# STM32MP13xx register map
File version: 1.5
CPU: CA7 r0p0, little endian, MPU, FPU, 4 interrupt priority bits
Registers are 32-bit, read-write, reset 0x0 unless marked. A register's access mark holds for its fields unless they carry their own. Offsets are from the block's base; [hi:lo] are bit positions; {n}, {i} and the like mark numbered series; 'fields as' and 'values as' point back to an identical list.

## RCC (part 7 of 7)
Base 0x50000000
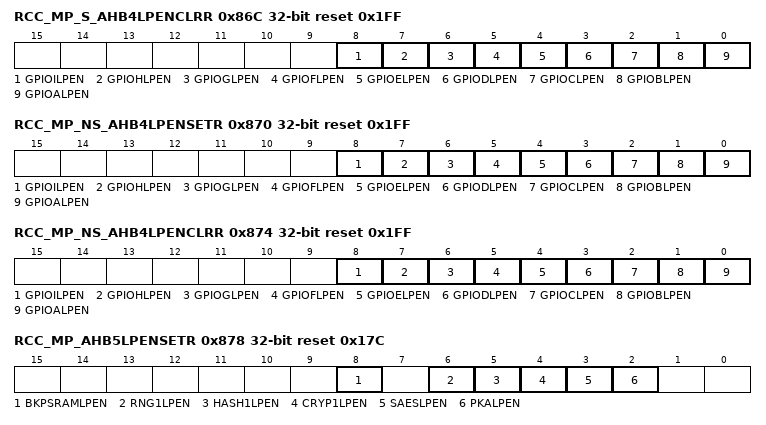
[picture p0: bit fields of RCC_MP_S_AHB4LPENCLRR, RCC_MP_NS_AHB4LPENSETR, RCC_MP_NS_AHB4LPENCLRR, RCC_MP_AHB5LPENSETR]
0x86C RCC_MP_S_AHB4LPENCLRR reset 0x1FF — This is a secure register, for disabling the clock of the secure (AHB4) GPIO ports
  [all] fields
    0=Writing '0' has no effect, reading '0' means that the peripheral clocks are disabled in CSleep; 1=Writing '1' disables the peripheral clocks in CSleep, reading '1' means that the peripheral clocks are enabled in CSleep
  [8] GPIOILPEN — GPIOI peripheral clocks enable during CSleep mode Cleared by (secure) software.
  [7] GPIOHLPEN — GPIOH peripheral clocks enable during CSleep mode Cleared by (secure) software.
  [6] GPIOGLPEN — GPIOG peripheral clocks enable during CSleep mode Cleared by (secure) software.
  [5] GPIOFLPEN — GPIOF peripheral clocks enable during CSleep mode Cleared by (secure) software.
  [4] GPIOELPEN — GPIOE peripheral clocks enable during CSleep mode Cleared by (secure) software.
  [3] GPIODLPEN — GPIOD peripheral clocks enable during CSleep mode Cleared by (secure) software.
  [2] GPIOCLPEN — GPIOC peripheral clocks enable during CSleep mode Cleared by (secure) software.
  [1] GPIOBLPEN — GPIOB peripheral clocks enable during CSleep mode Cleared by (secure) software.
  [0] GPIOALPEN — GPIOA peripheral clocks enable during CSleep mode Cleared by (secure) software.
0x870 RCC_MP_NS_AHB4LPENSETR reset 0x1FF — This is a non-secure register, for enabling the clock of the non-secure (AHB4) GPIO ports, as defined by the GPIO register file and more specifically the GPIOxSECCFGR.SECy control bit with x=A..I, and y = 0..15 (or 2 for x=I). This register is used in order to set the PERxLPEN bit of the corresponding peripheral. Writing '0' has no effect, reading will return the effective values of the corresponding bits. Writing a '1' sets the corresponding bit to '1'.
  [all] fields
    0=Writing '0' has no effect, reading '0' means that the peripheral clocks are disabled in CSleep; 1=Writing '1' enables the peripheral clocks in CSleep, reading '1' means that the peripheral clocks are enabled in CSleep
  [8] GPIOILPEN — GPIOI peripheral clocks enable during CSleep mode Set by software.
  [7] GPIOHLPEN — GPIOH peripheral clocks enable during CSleep mode Set by software.
  [6] GPIOGLPEN — GPIOG peripheral clocks enable during CSleep mode Set by software.
  [5] GPIOFLPEN — GPIOF peripheral clocks enable during CSleep mode Set by software.
  [4] GPIOELPEN — GPIOE peripheral clocks enable during CSleep mode Set by software.
  [3] GPIODLPEN — GPIOD peripheral clocks enable during CSleep mode Set by software.
  [2] GPIOCLPEN — GPIOC peripheral clocks enable during CSleep mode Set by software.
  [1] GPIOBLPEN — GPIOB peripheral clocks enable during CSleep mode Set by software.
  [0] GPIOALPEN — GPIOA peripheral clocks enable during CSleep mode Set by software.
0x874 RCC_MP_NS_AHB4LPENCLRR reset 0x1FF — This is a non-secure register, for disabling the clock of the non-secure (AHB4) GPIO ports, as defined by the GPIO register file and more specifically the GPIOxSECCFGR.SECy control bit with x=A..I, and y = 0..15 (or 2 for x=I).
  [all] fields
    values as the fields of RCC_MP_S_AHB4LPENCLRR
  [8] GPIOILPEN — GPIOI peripheral clocks enable during CSleep mode Cleared by software.
  [7] GPIOHLPEN — GPIOH peripheral clocks enable during CSleep mode Cleared by software.
  [6] GPIOGLPEN — GPIOG peripheral clocks enable during CSleep mode Cleared by software.
  [5] GPIOFLPEN — GPIOF peripheral clocks enable during CSleep mode Cleared by software.
  [4] GPIOELPEN — GPIOE peripheral clocks enable during CSleep mode Cleared by software.
  [3] GPIODLPEN — GPIOD peripheral clocks enable during CSleep mode Cleared by software.
  [2] GPIOCLPEN — GPIOC peripheral clocks enable during CSleep mode Cleared by software.
  [1] GPIOBLPEN — GPIOB peripheral clocks enable during CSleep mode Cleared by software.
  [0] GPIOALPEN — GPIOA peripheral clocks enable during CSleep mode Cleared by software.
0x878 RCC_MP_AHB5LPENSETR reset 0x17C — This register may be separately and securely write-protected at a field level, as detailed in the following register fields description. This register is used in order to set the PERxLPEN bit of the corresponding peripheral. Writing '0' has no effect, reading will return the effective values of the corresponding bits. Writing a '1' sets the corresponding bit to '1'.
  [all] fields
    values as the fields of RCC_MP_NS_AHB4LPENSETR
  [8] BKPSRAMLPEN — BKPSRAM clocks enable during CSleep mode If BKPSRAM is configured as secure via the corresponding DECPROT[1] field of the ETZPC register, a write access to this register field must be secure. A read access may be secure or non-secure. Set by software.
  [6] RNG1LPEN — RNG1 peripheral clocks enable during CSleep mode If RNG1 is configured as secure via the corresponding DECPROT[1] field of the ETZPC register, a write access to this register field must be secure. A read access may be secure or non-secure. Set by software.
  [5] HASH1LPEN — HASH peripheral clocks enable during CSleep mode If HASH is configured as secure via the corresponding DECPROT[1] field of the ETZPC register, a write access to this register field must be secure. A read access may be secure or non-secure. Set by software.
  [4] CRYP1LPEN — CRYP (3DES/AES) peripheral clocks enable during CSleep mode If CRYP is configured as secure via the corresponding DECPROT[1] field of the ETZPC register, a write access to this register field must be secure. A read access may be secure or non-secure. Set by software.
  [3] SAESLPEN — SAES peripheral clocks enable during CSleep mode If SAES is configured as secure via the corresponding DECPROT[1] field of the ETZPC register, a write access to this register field must be secure. A read access may be secure or non-secure. Set by software.
  [2] PKALPEN — PKA peripheral clocks enable during CSleep mode If PKA is configured as secure via the corresponding DECPROT[1] field of the ETZPC register, a write access to this register field must be secure. A read access may be secure or non-secure. Set by software.
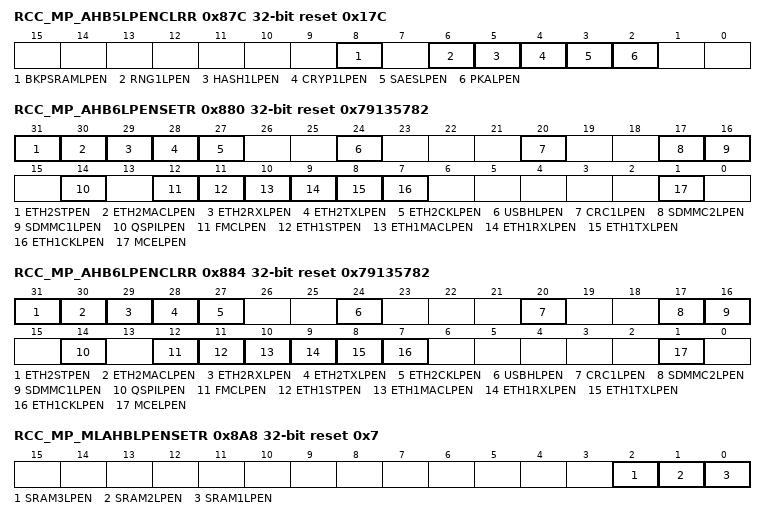
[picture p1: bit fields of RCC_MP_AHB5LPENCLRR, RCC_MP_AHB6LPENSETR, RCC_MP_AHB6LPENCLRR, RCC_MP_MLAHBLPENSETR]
0x87C RCC_MP_AHB5LPENCLRR reset 0x17C — This register may be separately and securely write-protected at a field level, as detailed in the following register fields description. This register is used in order to clear the PERxLPEN bit of the corresponding peripheral. Writing '0' has no effect, reading will return the effective values of the corresponding bits. Writing a '1' sets the corresponding bit to '0'.
  [all] fields
    values as the fields of RCC_MP_S_AHB4LPENCLRR
  [8] BKPSRAMLPEN — BKPSRAM clocks enable during CSleep mode If BKPSRAM is configured as secure via the corresponding DECPROT[1] field of the ETZPC register, a write access to this register field must be secure. A read access may be secure or non-secure. Cleared by software.
  [6] RNG1LPEN — RNG1 peripheral clocks enable during CSleep mode If RNG1 is configured as secure via the corresponding DECPROT[1] field of the ETZPC register, a write access to this register field must be secure. A read access may be secure or non-secure. Cleared by software.
  [5] HASH1LPEN — HASH peripheral clocks enable during CSleep mode If HASH is configured as secure via the corresponding DECPROT[1] field of the ETZPC register, a write access to this register field must be secure. A read access may be secure or non-secure. Cleared by software.
  [4] CRYP1LPEN — CRYP (3DES/AES) peripheral clocks enable during CSleep mode If CRYP is configured as secure via the corresponding DECPROT[1] field of the ETZPC register, a write access to this register field must be secure. A read access may be secure or non-secure. Cleared by software.
  [3] SAESLPEN — SAES peripheral clocks enable during CSleep mode If SAES is configured as secure via the corresponding DECPROT[1] field of the ETZPC register, a write access to this register field must be secure. A read access may be secure or non-secure. Cleared by software.
  [2] PKALPEN — PKA peripheral clocks enable during CSleep mode If PKA is configured as secure via the corresponding DECPROT[1] field of the ETZPC register, a write access to this register field must be secure. A read access may be secure or non-secure. Cleared by software.
0x880 RCC_MP_AHB6LPENSETR reset 0x79135782 — This register may be separately and securely write-protected at a field level, as detailed in the following register fields description. This register is used in order to set the PERxLPEN bit of the corresponding peripheral. Writing '0' has no effect, reading will return the effective values of the corresponding bits. Writing a '1' sets the corresponding bit to '1'.
  [31] ETH2STPEN — ETH2 peripheral clock enable during CStop mode If ETH2 is configured as secure via the corresponding DECPROT[1] field of the ETZPC register, a write access to this register field must be secure. A read access may be secure or non-secure. Set by software in order to allow the ETH2 block to receive from pads ETH2_TX_CLK and ETH2_RX_CLK clocks during CStop.
    0=Writing '0' has no effect, reading '0' means that the ETH2_TX_CLK and ETH2_RX_CLK clocks are disabled in CStop; 1=Writing '1' enables the ETH2_TX_CLK and ETH2_RX_CLK clocks in CStop, reading '1' means that the ETH2_TX_CLK and ETH2_RX_CLK clocks are enabled in CStop
  [30] ETH2MACLPEN — ETH2 MAC bus interface clock enable during CSleep mode (hclk6 and aclk) If ETH2 is configured as secure via the corresponding DECPROT[1] field of the ETZPC register, a write access to this register field must be secure. A read access may be secure or non-secure. Set by software.
    0=Writing '0' has no effect, reading '0' means that the bus interface clock is disabled in CSleep; 1=Writing '1' enables the bus interface clock in CSleep, reading '1' means that the bus interface clock is enabled in CSleep
  [29] ETH2RXLPEN — ETH2 reception clock enable during CSleep mode If ETH2 is configured as secure via the corresponding DECPROT[1] field of the ETZPC register, a write access to this register field must be secure. A read access may be secure or non-secure. Set by software.
    0=Writing '0' has no effect, reading '0' means that the reception clock is disabled in CSleep; 1=Writing '1' enables the reception clock in CSleep, reading '1' means that the reception clock is enabled in CSleep
  [28] ETH2TXLPEN — ETH2 transmission clock enable during CSleep mode If ETH2 is configured as secure via the corresponding DECPROT[1] field of the ETZPC register, a write access to this register field must be secure. A read access may be secure or non-secure. Set by software.
    0=Writing '0' has no effect, reading '0' means that the transmission clock is disabled in CSleep; 1=Writing '1' enables the transmission clock in CSleep, reading '1' means that the transmission clock is enabled in CSleep
  [27] ETH2CKLPEN — Enable of the ETH2 clock generated by the RCC (eth2_ker_ck) If ETH2 is configured as secure via the corresponding DECPROT[1] field of the ETZPC register, a write access to this register field must be secure. A read access may be secure or non-secure. Set by software.
    0=Writing '0' has no effect, reading '0' means that eth2_ker_ck clock is disabled in CSleep; 1=Writing '1' enables the eth2_ker_ck clock in CSleep, reading '1' means that the eth2_ker_ck clock is enabled in CSleep
  [24] USBHLPEN — USBH peripheral clocks enable during CSleep mode Set by software.
    values as the fields of RCC_MP_NS_AHB4LPENSETR
  [20] CRC1LPEN — CRC peripheral clocks enable during CSleep mode Set by software.
    values as the fields of RCC_MP_NS_AHB4LPENSETR
  [17] SDMMC2LPEN — SDMMC2 and SDMMC2 delay (DLYBSD2) block peripheral clocks enable during CSleep mode If SDMMC2 is configured as secure via the corresponding DECPROT[1] field of the ETZPC register, a write access to this register field must be secure. A read access may be secure or non-secure. Set by software.
    values as the fields of RCC_MP_NS_AHB4LPENSETR
  [16] SDMMC1LPEN — SDMMC1 and SDMMC1 delay (DLYBSD1) block peripheral clocks enable during CSleep mode If SDMMC1 is configured as secure via the corresponding DECPROT[1] field of the ETZPC register, a write access to this register field must be secure. A read access may be secure or non-secure. Set by software.
    values as the fields of RCC_MP_NS_AHB4LPENSETR
  [14] QSPILPEN — QUADSPI peripheral clocks enable during CSleep mode If QSPI is configured as secure via the corresponding DECPROT[1] field of the ETZPC register, a write access to this register field must be secure. A read access may be secure or non-secure. Set by software.
    values as the fields of RCC_MP_NS_AHB4LPENSETR
  [12] FMCLPEN — FMC peripheral clocks enable during CSleep mode If FMC is configured as secure via the corresponding DECPROT[1] field of the ETZPC register, a write access to this register field must be secure. A read access may be secure or non-secure. Set by software.
    values as the fields of RCC_MP_NS_AHB4LPENSETR
  [11] ETH1STPEN — ETH1 peripheral clock enable during CStop mode If ETH1 is configured as secure via the corresponding DECPROT[1] field of the ETZPC register, a write access to this register field must be secure. A read access may be secure or non-secure. Set by software in order to allow the ETH1 block to receive from pads ETH1_TX_CLK and ETH1_RX_CLK clocks during CStop.
    0=Writing '0' has no effect, reading '0' means that the ETH1_TX_CLK and ETH1_RX_CLK clocks are disabled in CStop; 1=Writing '1' enables the ETH1_TX_CLK and ETH1_RX_CLK clocks in CStop, reading '1' means that the ETH1_TX_CLK and ETH1_RX_CLK clocks are enabled in CStop
  [10] ETH1MACLPEN — ETH1 MAC bus interface clock enable during CSleep mode (hclk6 and aclk) If ETH1 is configured as secure via the corresponding DECPROT[1] field of the ETZPC register, a write access to this register field must be secure. A read access may be secure or non-secure. Set by software.
    values as ETH2MACLPEN
  [9] ETH1RXLPEN — ETH1 reception clock enable during CSleep mode If ETH1 is configured as secure via the corresponding DECPROT[1] field of the ETZPC register, a write access to this register field must be secure. A read access may be secure or non-secure. Set by software.
    values as ETH2RXLPEN
  [8] ETH1TXLPEN — ETH1 transmission clock enable during CSleep mode If ETH1 is configured as secure via the corresponding DECPROT[1] field of the ETZPC register, a write access to this register field must be secure. A read access may be secure or non-secure. Set by software.
    values as ETH2TXLPEN
  [7] ETH1CKLPEN — Enable of the ETH1 clock generated by the RCC (eth1_ker_ck) If ETH1 is configured as secure via the corresponding DECPROT[1] field of the ETZPC register, a write access to this register field must be secure. A read access may be secure or non-secure. Set by software.
    0=Writing '0' has no effect, reading '0' means that eth1_ker_ck clock is disabled in CSleep; 1=Writing '1' enables the eth1_ker_ck clock in CSleep, reading '1' means that the eth1_ker_ck clock is enabled in CSleep
  [1] MCELPEN — MCE peripheral clocks enable during CSleep mode If MCE is configured as secure via the corresponding DECPROT[1] field of the ETZPC register, a write access to this register field must be secure. A read access may be secure or non-secure. Set by software.
    values as the fields of RCC_MP_NS_AHB4LPENSETR
0x884 RCC_MP_AHB6LPENCLRR reset 0x79135782 — This register may be separately and securely write-protected at a field level.
  [31] ETH2STPEN — ETH2 peripheral clock enable during CStop mode If ETH2 is configured as secure via the corresponding DECPROT[1] field of the ETZPC register, a write access to this register field must be secure. A read access may be secure or non-secure. Cleared by software in order to allow the ETH2 block to receive from pads ETH2_TX_CLK and ETH2_RX_CLK clocks during CStop.
    0=Writing '0' has no effect, reading '0' means that the ETH2_TX_CLK and ETH2_RX_CLK clocks are disabled in CStop; 1=Writing '1' disables the ETH2_TX_CLK and ETH2_RX_CLK clocks in CStop, reading '1' means that the ETH2_TX_CLK and ETH2_RX_CLK clocks are enabled in CStop
  [30] ETH2MACLPEN — ETH2 MAC bus interface clock enable during CSleep mode (hclk6 and aclk) If ETH2 is configured as secure via the corresponding DECPROT[1] field of the ETZPC register, a write access to this register field must be secure. A read access may be secure or non-secure. Cleared by software.
    0=Writing '0' has no effect, reading '0' means that the bus interface clock is disabled in CSleep; 1=Writing '1' disables the bus interface clock in CSleep, reading '1' means that the bus interface clock is enabled in CSleep
  [29] ETH2RXLPEN — ETH2 reception clock enable during CSleep mode If ETH2 is configured as secure via the corresponding DECPROT[1] field of the ETZPC register, a write access to this register field must be secure. A read access may be secure or non-secure. Cleared by software.
    0=Writing '0' has no effect, reading '0' means that the reception clock is disabled in CSleep; 1=Writing '1' disables the reception clock in CSleep, reading '1' means that the reception clock is enabled in CSleep
  [28] ETH2TXLPEN — ETH2 transmission clock enable during CSleep mode If ETH2 is configured as secure via the corresponding DECPROT[1] field of the ETZPC register, a write access to this register field must be secure. A read access may be secure or non-secure. Cleared by software.
    0=Writing '0' has no effect, reading '0' means that the transmission clock is disabled in CSleep; 1=Writing '1' disables the transmission clock in CSleep, reading '1' means that the transmission clock is enabled in CSleep
  [27] ETH2CKLPEN — Enable of the ETH2 clock generated by the RCC (eth2_ker_ck) If ETH2 is configured as secure via the corresponding DECPROT[1] field of the ETZPC register, a write access to this register field must be secure. A read access may be secure or non-secure. Cleared by software.
    0=Writing '0' has no effect, reading '0' means that eth2_ker_ck clock is disabled in CSleep; 1=Writing '1' disables the eth2_ker_ck clock in CSleep, reading '1' means that the eth2_ker_ck clock is enabled in CSleep
  [24] USBHLPEN — USBH peripheral clocks enable during CSleep mode Cleared by software.
    values as the fields of RCC_MP_S_AHB4LPENCLRR
  [20] CRC1LPEN — CRC peripheral clocks enable during CSleep mode Cleared by software.
    values as the fields of RCC_MP_S_AHB4LPENCLRR
  [17] SDMMC2LPEN — SDMMC2 and SDMMC2 delay (DLYBSD2) block peripheral clocks enable during CSleep mode If SDMMC2 is configured as secure via the corresponding DECPROT[1] field of the ETZPC register, a write access to this register field must be secure. A read access may be secure or non-secure. Cleared by software.
    values as the fields of RCC_MP_S_AHB4LPENCLRR
  [16] SDMMC1LPEN — SDMMC1 and SDMMC1 delay (DLYBSD1) block peripheral clocks enable during CSleep mode If SDMMC1 is configured as secure via the corresponding DECPROT[1] field of the ETZPC register, a write access to this register field must be secure. A read access may be secure or non-secure. Cleared by software.
    values as the fields of RCC_MP_S_AHB4LPENCLRR
  [14] QSPILPEN — QUADSPI peripheral clocks enable during CSleep mode If QSPI is configured as secure via the corresponding DECPROT[1] field of the ETZPC register, a write access to this register field must be secure. A read access may be secure or non-secure. Cleared by software.
    values as the fields of RCC_MP_S_AHB4LPENCLRR
  [12] FMCLPEN — FMC peripheral clocks enable during CSleep mode If FMC is configured as secure via the corresponding DECPROT[1] field of the ETZPC register, a write access to this register field must be secure. A read access may be secure or non-secure. Cleared by software.
    values as the fields of RCC_MP_S_AHB4LPENCLRR
  [11] ETH1STPEN — ETH1 peripheral clock enable during CStop mode If ETH1 is configured as secure via the corresponding DECPROT[1] field of the ETZPC register, a write access to this register field must be secure. A read access may be secure or non-secure. Cleared by software in order to allow the ETH1 block to receive from pads ETH1_TX_CLK and ETH1_RX_CLK clocks during CStop.
    0=Writing '0' has no effect, reading '0' means that the ETH1_TX_CLK and ETH1_RX_CLK clocks are disabled in CStop; 1=Writing '1' disables the ETH1_TX_CLK and ETH1_RX_CLK clocks in CStop, reading '1' means that the ETH1_TX_CLK and ETH1_RX_CLK clocks are enabled in CStop
  [10] ETH1MACLPEN — ETH1 MAC bus interface clock enable during CSleep mode (hclk6 and aclk) If ETH1 is configured as secure via the corresponding DECPROT[1] field of the ETZPC register, a write access to this register field must be secure. A read access may be secure or non-secure. Cleared by software.
    values as ETH2MACLPEN
  [9] ETH1RXLPEN — ETH1 reception clock enable during CSleep mode If ETH1 is configured as secure via the corresponding DECPROT[1] field of the ETZPC register, a write access to this register field must be secure. A read access may be secure or non-secure. Cleared by software.
    values as ETH2RXLPEN
  [8] ETH1TXLPEN — ETH1 transmission clock enable during CSleep mode If ETH1 is configured as secure via the corresponding DECPROT[1] field of the ETZPC register, a write access to this register field must be secure. A read access may be secure or non-secure. Cleared by software.
    values as ETH2TXLPEN
  [7] ETH1CKLPEN — Enable of the ETH1 clock generated by the RCC (eth1_ker_ck) If ETH1 is configured as secure via the corresponding DECPROT[1] field of the ETZPC register, a write access to this register field must be secure. A read access may be secure or non-secure. Cleared by software.
    0=Writing '0' has no effect, reading '0' means that eth1_ker_ck clock is disabled in CSleep; 1=Writing '1' disables the eth1_ker_ck clock in CSleep, reading '1' means that the eth1_ker_ck clock is enabled in CSleep
  [1] MCELPEN — MCE peripheral clocks enable during CSleep mode If MCE is configured as secure via the corresponding DECPROT[1] field of the ETZPC register, a write access to this register field must be secure. A read access may be secure or non-secure. Cleared by software.
    values as the fields of RCC_MP_S_AHB4LPENCLRR
0x888 RCC_MP_S_AHB6LPENSETR reset 0x1 — This is a secure register for enabling the clock of the MDMA in Sleep mode when it is used as secure. A write access to this register field must be secure. A read access may be secure or non-secure. This register is used in order to set the PERxLPEN bit of the corresponding peripheral. Writing '0' has no effect, reading will return the effective values of the corresponding bits. Writing a '1' sets the corresponding bit to '1'.
  [0] MDMALPEN — MDMA peripheral clocks enable during CSleep mode Set by (secure) software.
    values as the fields of RCC_MP_NS_AHB4LPENSETR
0x88C RCC_MP_S_AHB6LPENCLRR reset 0x1 — This is a secure register for disabling the clock of the MDMA in Sleep mode when it is not used as secure. A write access to this register field must be secure. A read access may be secure or non-secure. This register is used in order to clear the PERxLPEN bit of the corresponding peripheral. Writing '0' has no effect, reading will return the effective values of the corresponding bits. Writing a '1' sets the corresponding bit to '0'.
  [0] MDMALPEN — MDMA peripheral clocks enable during CSleep mode Cleared by (secure) software.
    values as the fields of RCC_MP_S_AHB4LPENCLRR
0x890 RCC_MP_NS_AHB6LPENSETR reset 0x1 — This is a non-secure register for enabling the clock of the MDMA in Sleep mode when it is not used as secure. This register is used in order to set the PERxLPEN bit of the corresponding peripheral. Writing '0' has no effect, reading will return the effective values of the corresponding bits. Writing a '1' sets the corresponding bit to '1'.
  [0] MDMALPEN — MDMA peripheral clocks enable during CSleep mode Set by software.
    values as the fields of RCC_MP_NS_AHB4LPENSETR
0x894 RCC_MP_NS_AHB6LPENCLRR reset 0x1 — This is a non-secure register for disabling the clock of the MDMA in Sleep mode when it is not used as secure. This register is used in order to clear the PERxLPEN bit of the corresponding peripheral. Writing '0' has no effect, reading will return the effective values of the corresponding bits. Writing a '1' sets the corresponding bit to '0'.
  [0] MDMALPEN — MDMA peripheral clocks enable during CSleep mode Cleared by software.
    values as the fields of RCC_MP_S_AHB4LPENCLRR
0x898 RCC_MP_S_AXIMLPENSETR reset 0x1 — This is a secure register, for enabling the clock of the SYSRAM during CSleep mode. A write access to this register field must be secure. A read access may be secure or non-secure. This register is used in order to set the PERxLPEN bit of the corresponding peripheral. Writing '0' has no effect, reading will return the effective values of the corresponding bits. Writing a '1' sets the corresponding bit to '1'.
  [0] SYSRAMLPEN — SYSRAM interface clock enable during CSleep mode Set by (secure) software.
    0=Writing '0' has no effect, reading '0' means that the memory interface clock is disabled in CSleep; 1=Writing '1' enables the memory interface clock in CSleep, reading '1' means that the memory interface clock is enabled in CSleep
0x89C RCC_MP_S_AXIMLPENCLRR reset 0x1 — This is a secure register, for disabling the clock of the SYSRAM during CSleep mode.
  [0] SYSRAMLPEN — SYSRAM interface clock enable during CSleep mode Cleared by (secure) software.
    0=Writing '0' has no effect, reading '0' means that the memory interface is disabled in CSleep; 1=Writing '1' disables the memory interface in CSleep, reading '1' means that the memory interface is enabled in CSleep
0x8A0 RCC_MP_NS_AXIMLPENSETR reset 0x1 — This is a non-secure register, for enabling the clock of the SYSRAM during CSleep mode. This register is used in order to set the PERxLPEN bit of the corresponding peripheral. Writing '0' has no effect, reading will return the effective values of the corresponding bits. Writing a '1' sets the corresponding bit to '1'.
  [0] SYSRAMLPEN — SYSRAM interface clock enable during CSleep mode Set by software.
    values as RCC_MP_S_AXIMLPENSETR.SYSRAMLPEN
0x8A4 RCC_MP_NS_AXIMLPENCLRR reset 0x1 — This is a non-secure register, for disabling the clock of the SYSRAM during CSleep mode.
  [0] SYSRAMLPEN — SYSRAM interface clock enable during CSleep mode Cleared by software.
    values as RCC_MP_S_AXIMLPENCLRR.SYSRAMLPEN
0x8A8 RCC_MP_MLAHBLPENSETR reset 0x7 — This register may be separately and securely write-protected at a field level, as detailed in the following register fields description. This register is used in order to set the PERxLPEN bit of the corresponding peripheral. Writing '0' has no effect, reading will return the effective values of the corresponding bits. Writing a '1' sets the corresponding bit to '1'.
  [all] fields
    0=Writing '0' has no effect, reading '0' means that the memory interface clock is disabled in CSleep; 1=Writing '1' enables the memory interface clock in CSleep, reading '1' means that the memory interface is enabled in CSleep
  [2] SRAM3LPEN — SRAM3 interface clock enable during CSleep mode If SRAM3 is configured as secure via the corresponding DECPROT[1] field of the ETZPC register, a write access to this register field must be secure. A read access may be secure or non-secure. Set by software.
  [1] SRAM2LPEN — SRAM2 interface clock enable during CSleep mode If SRAM2 is configured as secure via the corresponding DECPROT[1] field of the ETZPC register, a write access to this register field must be secure. A read access may be secure or non-secure. Set by software.
  [0] SRAM1LPEN — SRAM1 interface clock enable during CSleep mode If SRAM1 is configured as secure via the corresponding DECPROT[1] field of the ETZPC register, a write access to this register field must be secure. A read access may be secure or non-secure. Set by software.
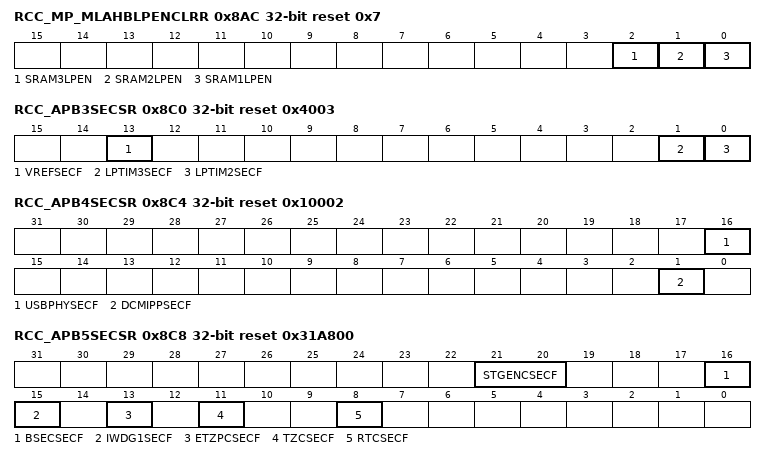
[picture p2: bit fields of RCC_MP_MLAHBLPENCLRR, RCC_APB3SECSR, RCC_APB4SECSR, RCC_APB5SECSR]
0x8AC RCC_MP_MLAHBLPENCLRR reset 0x7 — This register may be separately and securely write-protected at a field level
  [all] fields
    0=Writing '0' has no effect, reading '0' means that the memory interface clock is disabled in CSleep; 1=Writing '1' disables the memory interface clock in CSleep, reading '1' means that the memory interface is enabled in CSleep
  [2] SRAM3LPEN — SRAM3 interface clock enable during CSleep mode If SRAM3 is configured as secure via the corresponding DECPROT[1] field of the ETZPC register, a write access to this register field must be secure. A read access may be secure or non-secure. Cleared by software.
  [1] SRAM2LPEN — SRAM2 interface clock enable during CSleep mode If SRAM2 is configured as secure via the corresponding DECPROT[1] field of the ETZPC register, a write access to this register field must be secure. A read access may be secure or non-secure. Cleared by software.
  [0] SRAM1LPEN — SRAM1 interface clock enable during CSleep mode If SRAM1 is configured as secure via the corresponding DECPROT[1] field of the ETZPC register, a write access to this register field must be secure. A read access may be secure or non-secure. Cleared by software.
0x8C0 RCC_APB3SECSR ro reset 0x4003 — This read register reflects at a bit level the secure state of each APB3 securable peripheral, as configured via the corresponding DECPROT[1] field of the ETZPC register.
  [all] fields
    0=peripheral is non-secure; 1=peripheral is secure
  [13] VREFSECF — VREF block secure status flag This bit reflects the VREF block secure state, as configured via the corresponding DECPROT[1] field of the ETZPC register.
  [1] LPTIM3SECF — LPTIM3 block secure status flag This bit reflects the LPTIM3 block secure state, as configured via the corresponding DECPROT[1] field of the ETZPC register.
  [0] LPTIM2SECF — LPTIM2 block secure status flag This bit reflects the LPTIM2 block secure state, as configured via the corresponding DECPROT[1] field of the ETZPC register.
0x8C4 RCC_APB4SECSR ro reset 0x10002 — This read register reflects at a bit level the secure state of each APB4 securable peripheral, as configured via the corresponding DECPROT[1] field of the ETZPC register.
  [16] USBPHYSECF — USBPHY block secure status flag This bit reflects the USBPHY block secure state, as configured via the corresponding DECPROT[1] field of the ETZPC register.
    0=peripheral is non-secure; 1=peripheral is secure
  [1] DCMIPPSECF — DCMIPP block secure status flag This bit reflects the DCMIPP block secure state, as configured via the corresponding DECPROT[1] field of the ETZPC register.
    0=peripheral is non-secure; 1=peripheral is secure
0x8C8 RCC_APB5SECSR ro reset 0x31A800 — This read register reflects at a bit level the secure state of each APB5 secure or securable peripheral, as configured either via the corresponding DECPROT[1] field of the ETZPC register or via the TrustZone-aware peripheral itself.
  [21:20] STGENCSECF — STGENC block secure status flag This field reflects the STGENC block secure state, as configured via the corresponding DECPROT[1] field of the ETZPC register.
    0=peripheral is non-secure; 3=peripheral is secure
  [16] BSECSECF — BSEC block secure status flag This bit reflects the BSEC block secure state.
    0=peripheral is non-secure; 1=peripheral is secure
  [15] IWDG1SECF — IWDG1 block secure status flag This bit reflects the IWDG1 block secure state, as configured via the corresponding DECPROT[1] field of the ETZPC register.
    0=peripheral is non-secure; 1=peripheral is secure
  [13] ETZPCSECF — ETZPC block secure status flag This bit reflects the ETZPC block secure state.
    0=peripheral is non-secure; 1=peripheral is secure
  [11] TZCSECF — TZC block secure status flag This bit reflects the TZC block secure state.
    0=peripheral is non-secure; 1=peripheral is secure
  [8] RTCSECF — RTC block secure status flag This bit reflects the RTC block secure state. If at least one function of the RTC is configured as secure via the RTC_SECCFGR register (i.e. if the input signal rtc_sec driven by RTC is asserted), this bit is asserted.
    0=peripheral is non-secure (default); 1=peripheral is secure (at least one RTC sub-function)
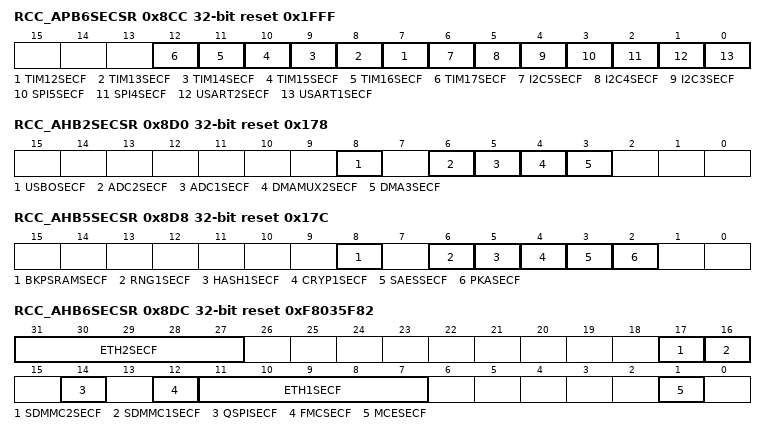
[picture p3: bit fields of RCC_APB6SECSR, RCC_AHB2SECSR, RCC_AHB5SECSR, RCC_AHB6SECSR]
0x8CC RCC_APB6SECSR ro reset 0x1FFF — This read register reflects at a bit level the secure state of each APB6 securable peripheral, as configured via the corresponding DECPROT[1] field of the ETZPC register.
  [all] fields
    0=peripheral is non-secure; 1=peripheral is secure
  [n-5] TIM{n}SECF (n=12..17) — TIM{n} block secure status flag This bit reflects the TIM{n} block secure state, as configured via the corresponding DECPROT[1] field of the ETZPC register.
  [6] I2C5SECF — I2C5 block secure status flag This bit reflects the I2C5 block secure state, as configured via the corresponding DECPROT[1] field of the ETZPC register.
  [5] I2C4SECF — I2C4 block secure status flag This bit reflects the I2C4 block secure state, as configured via the corresponding DECPROT[1] field of the ETZPC register.
  [4] I2C3SECF — I2C3 block secure status flag This bit reflects the I2C3 block secure state, as configured via the corresponding DECPROT[1] field of the ETZPC register.
  [3] SPI5SECF — SPI5 block secure status flag This bit reflects the SPI5 block secure state, as configured via the corresponding DECPROT[1] field of the ETZPC register.
  [2] SPI4SECF — SPI4 block secure status flag This bit reflects the SPI4 block secure state, as configured via the corresponding DECPROT[1] field of the ETZPC register.
  [1] USART2SECF — USART2 block secure status flag This bit reflects the USART2 block secure state, as configured via the corresponding DECPROT[1] field of the ETZPC register.
  [0] USART1SECF — USART1 block secure status flag This bit reflects the USART1 block secure state, as configured via the corresponding DECPROT[1] field of the ETZPC register.
0x8D0 RCC_AHB2SECSR ro reset 0x178 — This read register reflects at a bit level the secure state of each AHB2 securable peripheral, as configured via the corresponding DECPROT[1] field of the ETZPC register.
  [all] fields
    0=peripheral is non-secure; 1=peripheral is secure
  [8] USBOSECF — USBO block secure status flag This bit reflects the USBO block secure state, as configured via the corresponding DECPROT[1] field of the ETZPC register.
  [6] ADC2SECF — ADC2 block secure status flag This bit reflects the ADC2 block secure state, as configured via the corresponding DECPROT[1] field of the ETZPC register.
  [5] ADC1SECF — ADC1 block secure status flag This bit reflects the ADC1 block secure state, as configured via the corresponding DECPROT[1] field of the ETZPC register.
  [4] DMAMUX2SECF — DMAMUX2 block secure status flag This bit reflects the DMAMUX2 block secure state, as configured via the corresponding DECPROT[1] field of the ETZPC register.
  [3] DMA3SECF — DMA3 block secure status flag This bit reflects the DMA3 block secure state, as configured via the corresponding DECPROT[1] field of the ETZPC register.
0x8D4 RCC_AHB4SECSR ro reset 0x4000 — This read register reflects at a bit level the secure state of each AHB4 securable peripheral, as configured either via the corresponding DECPROT[1] field of the ETZPC register or via the TrustZone-aware peripheral itself.
  [15] TSCSECF — TSC block secure status flag This bit reflects the TSC block secure state, as configured via the corresponding DECPROT[1] field of the ETZPC register.
    0=peripheral is non-secure; 1=peripheral is secure
0x8D8 RCC_AHB5SECSR ro reset 0x17C — This read register reflects at a bit level the secure state of each AHB5 securable peripheral, as configured via the corresponding DECPROT[1] field of the ETZPC register.
  [all] fields
    0=peripheral is non-secure; 1=peripheral is secure
  [8] BKPSRAMSECF — BKPSRAM block secure status flag This bit reflects the BKPSRAM block secure state, as configured via the corresponding DECPROT[1] field of the ETZPC register.
  [6] RNG1SECF — RNG1 block secure status flag This bit reflects the RNG1 block secure state, as configured via the corresponding DECPROT[1] field of the ETZPC register.
  [5] HASH1SECF — HASH1 block secure status flag This bit reflects the HASH1 block secure state, as configured via the corresponding DECPROT[1] field of the ETZPC register.
  [4] CRYP1SECF — CRYP1 block secure status flag This bit reflects the CRYP1 block secure state, as configured via the corresponding DECPROT[1] field of the ETZPC register.
  [3] SAESSECF — SAES block secure status flag This bit reflects the SAES block secure state, as configured via the corresponding DECPROT[1] field of the ETZPC register.
  [2] PKASECF — PKA block secure status flag This bit reflects the PKA block secure state, as configured via the corresponding DECPROT[1] field of the ETZPC register.
0x8DC RCC_AHB6SECSR ro reset 0xF8035F82 — This read register reflects at a bit level the secure state of each AHB6 securable peripheral, as configured via the corresponding DECPROT[1] field of the ETZPC register.
  [31:27] ETH2SECF — ETH2 block secure status flag This field reflects the ETH2 block secure state, as configured via the corresponding DECPROT[1] field of the ETZPC register.
    0=peripheral is non-secure; 31=peripheral is secure
  [17] SDMMC2SECF — SDMMC2 block secure status flag This bit reflects the SDMMC2 block secure state, as configured via the corresponding DECPROT[1] field of the ETZPC register.
    0=peripheral is non-secure; 1=peripheral is secure
  [16] SDMMC1SECF — SDMMC1 block secure status flag This bit reflects the SDMMC1 block secure state, as configured via the corresponding DECPROT[1] field of the ETZPC register.
    0=peripheral is non-secure; 1=peripheral is secure
  [14] QSPISECF — QSPI block secure status flag This bit reflects the QSPI block secure state, as configured via the corresponding DECPROT[1] field of the ETZPC register.
    0=peripheral is non-secure; 1=peripheral is secure
  [12] FMCSECF — FMC block secure status flag This bit reflects the FMC block secure state, as configured via the corresponding DECPROT[1] field of the ETZPC register.
    0=peripheral is non-secure; 1=peripheral is secure
  [11:7] ETH1SECF — ETH1 block secure status flag This field reflects the ETH1 block secure state, as configured via the corresponding DECPROT[1] field of the ETZPC register.
    0=peripheral is non-secure; 31=peripheral is secure
  [1] MCESECF — MCE block secure status flag This bit reflects the MCE block secure state, as configured via the corresponding DECPROT[1] field of the ETZPC register.
    0=peripheral is non-secure; 1=peripheral is secure
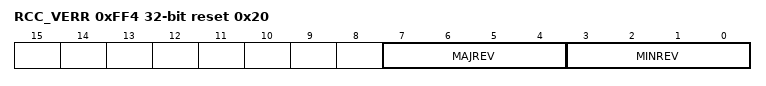
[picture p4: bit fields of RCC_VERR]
0xFF4 RCC_VERR ro reset 0x20 — This register gives the IP version
  [7:4] MAJREV — Major Revision of the IP
  [3:0] MINREV — Minor Revision of the IP
0xFF8 RCC_IDR ro reset 0x1 — This register gives the unique identifier of the RCC
  [31:0] ID — Identifier of the RCC
0xFFC RCC_SIDR ro reset 0xA3C5DD04 — This register gives the decoding space, which is for the RCC of 4 kB.
  [31:0] SID — Decoding space is 4 kbytes
